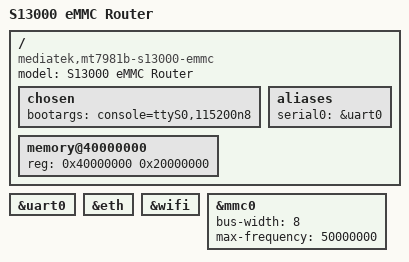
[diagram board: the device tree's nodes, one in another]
/dts-v1/;

/ {
    compatible = "mediatek,mt7981b-s13000-emmc", "mediatek,mt7981b";
    model = "S13000 eMMC Router";

    chosen {
        bootargs = "console=ttyS0,115200n8";
    };
};

#include "mt7981b.dtsi"

/ {
    memory@40000000 {
        device_type = "memory";
        reg = <0x40000000 0x20000000>;
    };

    aliases {
        serial0 = &uart0;
    };
};

&uart0 {
    status = "okay";
};

&eth {
    status = "okay";
};

&wifi {
    status = "okay";
};

&mmc0 {
    status = "okay";
    bus-width = <8>;
    max-frequency = <50000000>;
};
